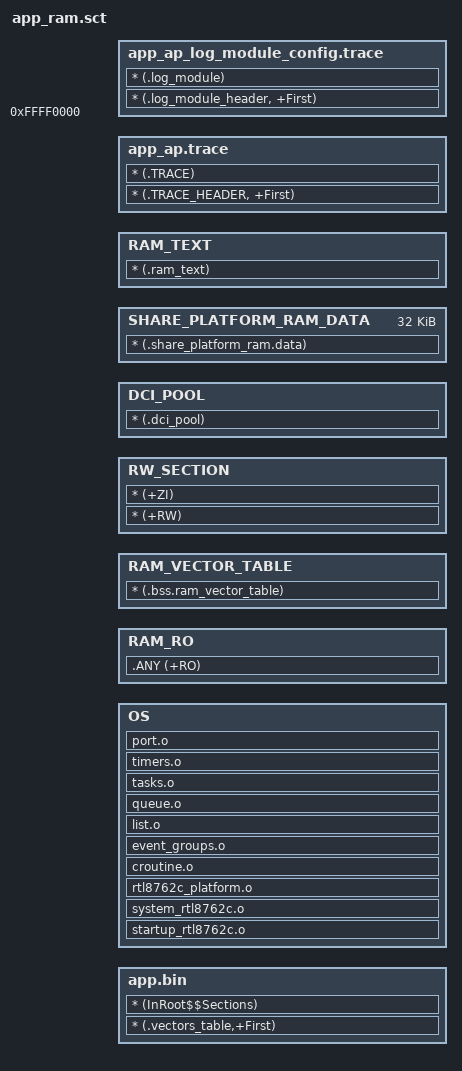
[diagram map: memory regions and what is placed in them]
#!armclang --target=arm-arm-none-eabi -march=armv8-m.main -E -x c
#include "..\..\..\boot\ap_boot\inc\rom_defines.h"
#include ".\inc\mem_config.h"
#include ".\inc\mem_cfg_int.h"
#include "..\..\..\..\kernel\logging\inc\rtl87x3k\trace_file_address.h"
; *************************************************************
; *** Scatter-Loading Description File generated by uVision ***
; *************************************************************

#define RW_SECTION_SIZE   DATA_RAM_VECTOR_TABLE_SIZE
#define RW_SECTION_ADR    DATA_RAM_VECTOR_TABLE_ADDR

#define RAM_LOAD_BASE   CODE_RAM_LOAD_ADDR
#define RAM_LOAD_SIZE   CODE_RAM_LOAD_SIZE

#define SHARE_PLATFORM_RAM_DATA_ADDR    SHARED_SRAM_BASE
#define SHARE_PLATFORM_RAM_DATA_SIZE    (32 * 1024)

;LOAD_BUFFER_RAM EXT0_ADDR EXT0_SIZE
;{
;    TEST_BUFFER_DATA +0
;    {
;        * (.ram.buffer)
;    }
;}

;LOAD_DATA_RAM0 DATA_SRAM0_ADDR DATA_SRAM0_SIZE
;{

;    TEST_DATA_RAM0 +0
;    {
;        * (.ram.data0)
;    }
;}

;LOAD_DATA_RAM1 DATA_RAM1_ADR DATA_RAM1_SIZE
;{

;    TEST_DATA_RAM1 +0
;    {
;        * (.ram.data1)
;    }

;}

LOAD_ITCM1 RAM_LOAD_BASE RAM_LOAD_SIZE
{   

    app.bin +0
    {
        * (.vectors_table,+First)
;        * (RESET)
        * (InRoot$$Sections)
	}	
	
    OS  +0
    {
        startup_rtl8762c.o
        system_rtl8762c.o
        rtl8762c_platform.o
        croutine.o
        event_groups.o
        list.o
        queue.o
        tasks.o
        timers.o
        port.o
    }
    
    RAM_RO +0
    {
        .ANY (+RO)   
    }
;    TEST_DATA_RAM +0
;    {
;        * (.ram.data)
;    }
	
	RAM_VECTOR_TABLE RW_SECTION_ADR ALIGN 128
	{
		* (.bss.ram_vector_table)
	}
	
	RW_SECTION +0
	{
		* (+RW)
        * (+ZI)
	}
	ScatterAssert((ImageLength(RAM_VECTOR_TABLE) + ImageLength(RW_SECTION)) < RW_SECTION_SIZE)

    ; DCI test framebuffer pool. Its own execution region on purpose: left inside
    ; RW_SECTION the ScatterAssert above rejects it, since one 160x120 RGB565 frame is
    ; 38432 B against a 10 KB budget. See DCI_POOL_SIZE in inc/mem_config.h.
    DCI_POOL DCI_POOL_ADDR DCI_POOL_SIZE
    {
        * (.dci_pool)
    }

    SHARE_PLATFORM_RAM_DATA SHARE_PLATFORM_RAM_DATA_ADDR SHARE_PLATFORM_RAM_DATA_SIZE
    {
        * (.share_platform_ram.data)
    }
	RAM_TEXT CODE_RAM_TEXT_ADDR CODE_RAM_TEXT_SIZE
    {
        * (.ram_text)
    }
}

;LOAD_SHARE_RAM DSP_SHM_ADDR DSP_SHM_SIZE
;{
;    TEST_SHARE_DATA +0
;    {
;        * (.ram.share.data)
;    }
;}
LOAD_ROM_NP_TRACE ROM_NP_TRACE_START ROM_NP_TRACE_SIZE
{
    app_ap.trace +0
    {
        * (.TRACE_HEADER, +First)
        * (.TRACE)
    }
}
LOAD_LOG_MODULE_TRACE 0xffff0000
{
    app_ap_log_module_config.trace 0xffff0000
    {
        * (.log_module_header, +First)
        * (.log_module)
    }
}


